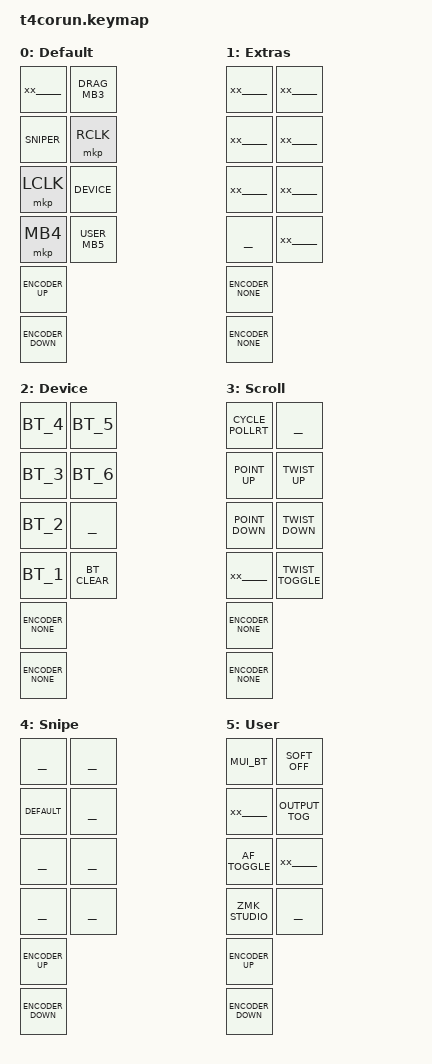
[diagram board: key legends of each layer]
#include "t4corun.h"
#include "t4co_feedback.dtsi"
#include "t4co_behaviors.dtsi"

/ {
    /*
     * This section deletes the keymap and trackball nodes so
     * I can replace them
     *
     * It also removes unused behaviors and macros to save memory
     * I find I don't use all the OS Swappable UCCPR macros
     */

    reset {
        /delete-node/ keymap;
        /delete-node/ trackball;
    };

    behaviors {
        /delete-node/ click-double-click-hold;
        /delete-node/ click-double-click-copy-paste;
        /delete-node/ ltmkp;
        /delete-node/ bst_copy;
        /delete-node/ bst_paste;
        /delete-node/ bst_cut;
        /delete-node/ bst_undo;
        /delete-node/ bst_tog;
    };

    macros {
        /delete-node/ winlin_copy;
        /delete-node/ macos_copy;
        /delete-node/ winlin_paste;
        /delete-node/ macos_paste;
        /delete-node/ winlin_cut;
        /delete-node/ macos_cut;
        /delete-node/ winlin_undo;
        /delete-node/ macos_undo;
        /delete-node/ scroll_down;
        /delete-node/ scroll_up;
        /delete-node/ scroll_left;
        /delete-node/ scroll_right;
    };
};


/ {
    keymap {
        compatible = "zmk,keymap";

        default_layer {
            display-name = "Default";
            DECLARE_ENCODERS;
            bindings = <
                // buttons
                _____xx_____    DRAG_MB3
                SNIPER          &mkp RCLK
                &mkp LCLK       DEVICE
                &mkp MB4        USER_MB5

                // rotary encoders
                ENCODER_UP
                ENCODER_DOWN
            >;
        };

        layer1 {
            display-name = "Extras";
            DECLARE_ENCODERS;
            bindings = <
                _____xx_____    _____xx_____
                _____xx_____    _____xx_____
                _____xx_____    _____xx_____
                ____________    _____xx_____

                ENCODER_NONE
                ENCODER_NONE
            >;
        };

        layer2 {
            display-name = "Device";
            DECLARE_ENCODERS;
            bindings = <
                BT_4            BT_5
                BT_3            BT_6
                BT_2            ____________
                BT_1            BT_CLEAR

                ENCODER_NONE
                ENCODER_NONE
            >;
        };

        layer3 {
            display-name = "Scroll";
            DECLARE_ENCODERS;
            bindings = <
                CYCLE_POLLRT    ____________
                POINT_UP        TWIST_UP
                POINT_DOWN      TWIST_DOWN
                _____xx_____    TWIST_TOGGLE

                ENCODER_NONE
                ENCODER_NONE
            >;
        };

        layer4 {
            display-name = "Snipe";
            DECLARE_ENCODERS;
            bindings = <
                ____________    ____________
                DEFAULT         ____________
                ____________    ____________
                ____________    ____________

                ENCODER_UP
                ENCODER_DOWN
            >;
        };

        layer5 {
            display-name = "User";
            DECLARE_ENCODERS;
            bindings = <
                MUI_BT          SOFT_OFF
                _____xx_____    OUTPUT_TOG
                AF_TOGGLE       _____xx_____
                ZMK_STUDIO      ____________

                ENCODER_UP
                ENCODER_DOWN
            >;
        };
    };

    trackball {
        //input-processors =  <&zip_scroll_scaler TWIST_MPLY TWIST_DIV>,
        input-processors =  <&zip_bistable_twist_scaler>,
                            <&zip_pointer_accel>,
                            <&zip_scroll_accel>,
                            <&zip_rotate_pointer>,
                            //<&zip_rotate_scroll>,
                            <&esb_ip>,
                            <&zip_ble_report_rate_limit>;

        scroll {
            layers = <LAYER_SCROLL>;
            input-processors =  <&zip_bistable_scroll_xy_scaler>,
                                <&zip_axis_clamper>,
                                <&zip_xy_to_scroll_mapper>,
                                <&zip_scroll_transform INPUT_TRANSFORM_Y_INVERT>,
                                <&zip_dragscroll_accel>,
                                <&zip_rotate_scroll>,
                                <&esb_ip>,
                                <&zip_ble_report_rate_limit>;
        };

        snipe {
            layers = <LAYER_SNIPE>;
            //input-processors =  <&zip_xy_scaler SNIPE_MPLY SNIPE_DIV>,
            input-processors =  <&zip_bistable_snipe_scaler>,
                                <&zip_rotate_pointer>,
                                //<&zip_rotate_scroll>,
                                <&esb_ip>,
                                <&zip_ble_report_rate_limit>;
        };
    };
};
